# MB9AF31xK register map
Vendor: Cypress; File version: 2.1
CPU: CM3 r2p1, little endian, MPU, no FPU, 4 interrupt priority bits
Registers are 32-bit, read-write, reset 0x0 unless marked. A register's access mark holds for its fields unless they carry their own. Offsets are from the block's base; [hi:lo] are bit positions; {n}, {i} and the like mark numbered series; 'fields as' and 'values as' point back to an identical list.

## MFS_NFC — I2C Auxiliary Noise Filter Setting Register
Base 0x40038800
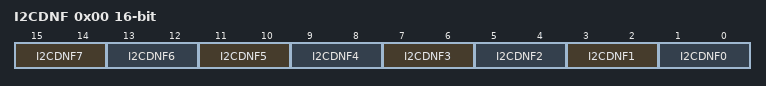
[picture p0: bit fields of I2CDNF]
0x00 I2CDNF 16-bit — I2C Auxiliary Noise Filter Setting Register [BHW]
  [15:14] I2CDNF7 — Auxiliary noise filter additional step select bits for I2C ch.7
  [13:12] I2CDNF6 — Auxiliary noise filter additional step select bits for I2C ch.6
  [11:10] I2CDNF5 — Auxiliary noise filter additional step select bits for I2C ch.5
  [9:8] I2CDNF4 — Auxiliary noise filter additional step select bits for I2C ch.4
  [7:6] I2CDNF3 — Auxiliary noise filter additional step select bits for I2C ch.3
  [5:4] I2CDNF2 — Auxiliary noise filter additional step select bits for I2C ch.2
  [3:2] I2CDNF1 — Auxiliary noise filter additional step select bits for I2C ch.1
  [1:0] I2CDNF0 — Auxiliary noise filter additional step select bits for I2C ch.0

## CRC — CRC Registers
Base 0x40039000
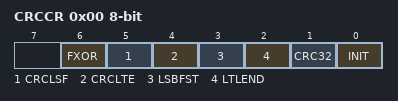
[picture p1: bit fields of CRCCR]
0x00 CRCCR 8-bit — CRC Control Register [BHW]
  [6] FXOR — Final XOR control bit
  [5] CRCLSF — CRC result bit-order setting bit
  [4] CRCLTE — CRC result byte-order setting bit
  [3] LSBFST — Bit-order setting bit
  [2] LTLEND — Byte-order setting bit
  [1] CRC32 — CRC mode selection bit
  [0] INIT — Initialization bit
0x04 CRCINIT reset 0xFFFFFFFF — Initial Value Register [BHW]
  [31:0] D — Initial value
0x08 CRCIN — Input Data Register [BHW]
  [31:0] D — Input data
0x0C CRCR ro reset 0xFFFFFFFF — CRC Register [BHW]
  [31:0] D — CRC Data

## WC — Watch Counter
Base 0x4003A000
0x00 WCRD 8-bit ro — Watch Counter Read Register [BHW]
  [5:0] CTR — counter value
0x01 WCRL 8-bit — Watch Counter Reload Register [BHW]
  [5:0] RLC — reload value
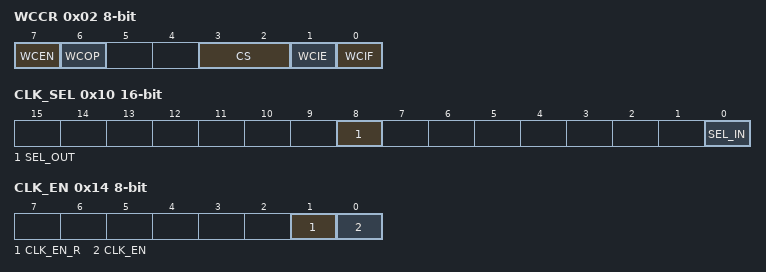
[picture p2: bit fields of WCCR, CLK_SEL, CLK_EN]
0x02 WCCR 8-bit — Watch Counter Control Register [BHW]
  [7] WCEN — Watch counter operation enable bit
  [6] WCOP ro — Watch counter operating state flag
  [3:2] CS — Count clock select bits
  [1] WCIE — Interrupt request enable bit
  [0] WCIF — Interrupt request flag bit
0x10 CLK_SEL 16-bit — Clock Selection Register [BHW]
  [8] SEL_OUT — Output clock selection bit
  [0] SEL_IN — Input clock selection bit
0x14 CLK_EN 8-bit — Division Clock Enable Register [BHW]
  [1] CLK_EN_R — Division clock enable read bit
  [0] CLK_EN — Division clock enable bit

## DMAC — DMAC Registers
Base 0x40060000
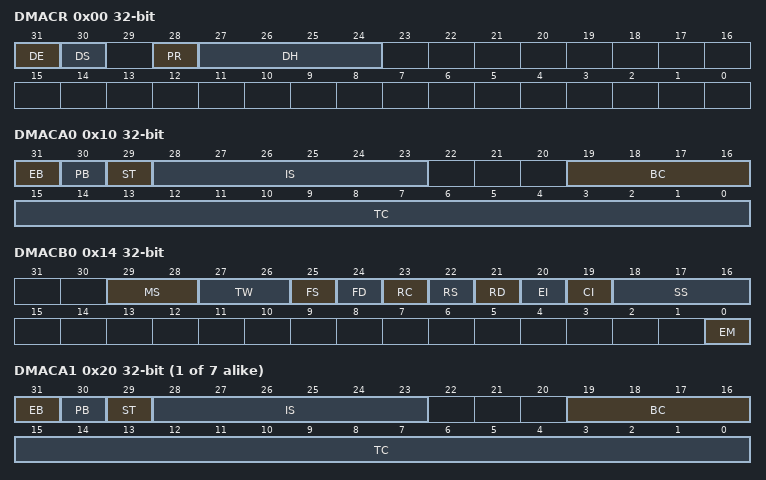
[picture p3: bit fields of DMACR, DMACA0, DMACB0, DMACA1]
0x00 DMACR — Entire DMAC Configuration Register [BHW]
  [31] DE — DMA Enable (all-channel operation enable bit)
  [30] DS — DMA Stop
  [28] PR — Priority Rotation
  [27:24] DH — DMA Halt (All-channel pause bit)
0x10 DMACA0 — Configuration A Register [BHW]
  [31] EB — Enable bit (individual-channel operation enable bit)
  [30] PB — Pause bit (individual-channel pause bit)
  [29] ST — Software Trigger
  [28:23] IS — Input Select
  [19:16] BC — Block Count
  [15:0] TC — Transfer Count
0x14 DMACB0 — Configuration B Register [BHW]
  [29:28] MS — Mode Select
  [27:26] TW — Transfer Width
  [25] FS — Fixed Source
  [24] FD — Fixed Destination
  [23] RC — Reload Count (BC/TC reload)
  [22] RS — Reload Source
  [21] RD — Reload Destination
  [20] EI — Error Interrupt (unsuccessful transfer completion interrupt enable)
  [19] CI — Completion Interrupt (successful transfer completion interrupt enable)
  [18:16] SS — Stop Status (stop status notification)
  [0] EM — Enable bit Mask (EB bit clear mask)
{0x18+0x10*i} DMACSA{i} (i=0..7) — Transfer Source Address Register {i} [BHW]
{0x1C+0x10*i} DMACDA{i} (i=0..7) — Transfer Destination Address Register {i} [BHW]
{0x10+0x10*i} DMACA{i} (i=1..7) — Configuration A Register {i} [BHW]
  fields as DMACA0
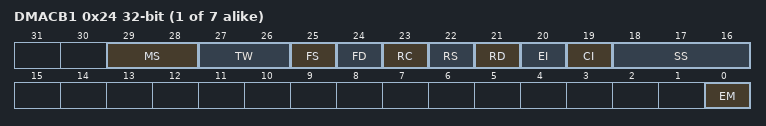
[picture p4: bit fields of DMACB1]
{0x14+0x10*i} DMACB{i} (i=1..7) — Configuration B Register {i} [BHW]
  fields as DMACB0

## WORKFLASH_IF — WorkFlash Memory
Base 0x200E0000
0x00 WFASZR reset 0x1 — WorkFlash Access Size Register [BHW]
  [0] ASZ — WorkFlash Access Size
0x04 WFRWTR (reset mask 0x6) — WorkFlash Read Wait Register [BHW]
  [2:0] RWT — Read Wait Cycle
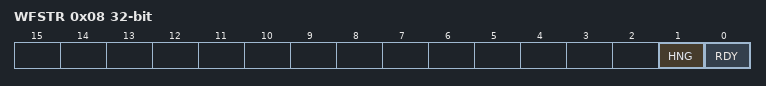
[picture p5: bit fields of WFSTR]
0x08 WFSTR ro (reset mask 0x2) — WorkFlash Status Register [BHW]
  [1] HNG — WorkFlash Hang
  [0] RDY — WorkFlash Rdy
